VERSION ""

NS_ :

BS_:

BU_: XXX 0

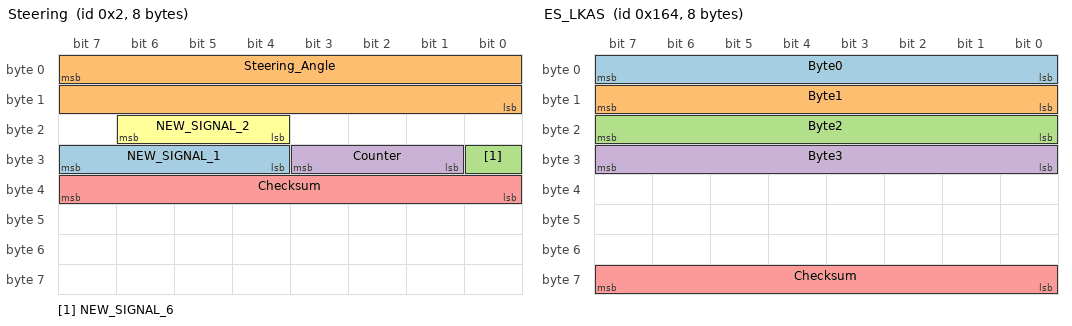
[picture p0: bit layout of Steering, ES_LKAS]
BO_ 2 Steering: 8 XXX
 SG_ NEW_SIGNAL_1 : 31|4@0- (1,0) [0|65535] "" XXX
 SG_ Steering_Angle : 7|16@0- (0.1,0) [-497|500] "degree" XXX
 SG_ NEW_SIGNAL_6 : 24|1@1+ (1,0) [0|3] "" XXX
 SG_ Counter : 25|3@1+ (1,0) [0|15] "" XXX
 SG_ Checksum : 32|8@1+ (1,0) [0|255] "" XXX
 SG_ NEW_SIGNAL_2 : 22|3@0+ (1,0) [0|7] "" XXX

BO_ 212 WHEEL_SPEEDS: 8 XXX
 SG_ FR : 16|16@1+ (0.0592,0) [0|255] "KPH" XXX
 SG_ RR : 48|16@1+ (0.0592,0) [0|127] "KPH" XXX
 SG_ RL : 32|16@1+ (0.0592,0) [0|255] "KPH" XXX
 SG_ FL : 0|16@1+ (0.0592,0) [2|255] "KPH" XXX
 SG_ Message : 7|64@0+ (1,0) [0|15] "" XXX

BO_ 352 ES_Brake: 8 XXX
 SG_ Counter : 48|3@1+ (1,0) [0|7] "" XXX
 SG_ Checksum : 56|8@1+ (1,0) [0|7] "" XXX
 SG_ Cruise_Activated : 23|1@0+ (1,0) [0|3] "" XXX
 SG_ Brake_On : 22|1@0+ (1,0) [0|3] "" XXX
 SG_ Brake_Light : 20|1@0+ (1,0) [0|2047] "" XXX
 SG_ Brake_Pressure : 0|11@1+ (1,0) [0|255] "" XXX
 SG_ Message : 7|64@0+ (1,0) [0|15] "" XXX

BO_ 353 ES_CruiseThrottle: 8 XXX
 SG_ Throttle_Cruise : 0|12@1+ (1,0) [0|255] "" XXX
 SG_ Counter_1 : 46|3@0+ (1,0) [0|15] "" XXX
 SG_ Wheel_stop : 22|1@0+ (1,0) [0|3] "" XXX
 SG_ CloseDistance : 24|8@1+ (1,0) [0|255] "" XXX
 SG_ Unknown : 18|1@1+ (1,0) [0|7] "" XXX
 SG_ Button_Speed_Down : 49|1@1+ (1,0) [0|3] "" XXX
 SG_ Button_Resume : 50|1@1+ (1,0) [0|15] "" XXX
 SG_ NEW_SIGNAL_3_Blank : 15|4@0+ (1,0) [0|15] "" XXX
 SG_ NEW_SIGNAL_2_Blank : 48|1@1+ (1,0) [0|3] "" XXX
 SG_ Checksum : 56|8@1+ (1,0) [0|15] "" XXX
 SG_ NEW_SIGNAL_9 : 17|1@1+ (1,0) [0|3] "" XXX
 SG_ Cruise_Activatedish : 16|1@1+ (1,0) [0|7] "" XXX
 SG_ NEW_SIGNAL_6_Blank : 23|1@0+ (1,0) [0|7] "" XXX
 SG_ DistanceSwap : 21|1@0+ (1,0) [0|3] "" XXX
 SG_ Brake_On : 20|1@0+ (1,0) [0|7] "" XXX
 SG_ Message : 7|64@0+ (1,0) [0|15] "" XXX

BO_ 354 ES_RPM: 8 XXX
 SG_ NEW_SIGNAL_2 : 8|1@1+ (1,0) [0|7] "" XXX
 SG_ Counter : 48|3@1+ (1,0) [0|7] "" XXX
 SG_ Cruise_Activated : 9|1@0+ (1,0) [0|3] "" XXX
 SG_ Checksum : 39|8@0+ (1,0) [0|65535] "" XXX
 SG_ RPM : 16|16@1+ (1,0) [0|255] "" XXX
 SG_ Message : 7|64@0+ (1,0) [0|15] "" XXX

BO_ 356 ES_LKAS: 8 XXX
 SG_ Byte0 : 7|8@0+ (1,0) [0|7] "" XXX
 SG_ Byte1 : 15|8@0+ (1,0) [0|7] "" XXX
 SG_ Byte2 : 23|8@0+ (1,0) [0|3] "" XXX
 SG_ Byte3 : 31|8@0+ (1,0) [0|7] "" XXX
 SG_ Checksum : 63|8@0+ (1,0) [0|15] "" XXX

BO_ 358 ES_Status: 8 XXX
 SG_ Counter : 39|3@0+ (1,0) [0|7] "" XXX
 SG_ Cruise_On : 16|1@1+ (1,0) [0|7] "" XXX
 SG_ Cruise_Activated : 17|1@1+ (1,0) [0|3] "" XXX
 SG_ Obstacle_Distance : 48|4@1+ (1,0) [0|15] "" XXX
 SG_ Cruise_Off : 22|1@0+ (1,0) [0|3] "" XXX
 SG_ Saved_Speed : 24|8@1+ (1,0) [0|255] "" XXX
 SG_ Car_Follow : 46|1@1+ (1,0) [0|255] "" XXX
 SG_ Driver_Input : 20|1@0+ (1,0) [0|15] "" XXX
 SG_ WHEELS_MOVING_2015 : 19|1@1+ (1,0) [0|3] "" XXX
 SG_ Untitled_Blank : 18|1@0+ (1,0) [0|3] "" XXX
 SG_ NEW_SIGNAL_6_Blank : 21|1@0+ (1,0) [0|3] "" XXX
 SG_ NEW_SIGNAL_5_Blank : 33|1@1+ (1,0) [0|3] "" XXX
 SG_ NEW_SIGNAL_4_Blank : 34|1@1+ (1,0) [0|7] "" XXX
 SG_ NEW_SIGNAL_1 : 35|1@0+ (1,0) [0|31] "" XXX
 SG_ Steep_Hill_Disengage : 44|1@0+ (1,0) [0|3] "" XXX
 SG_ 3SecondDisengage : 13|2@0+ (1,0) [0|3] "" XXX
 SG_ Not_Ready_Startup : 0|3@1+ (1,0) [0|7] "" XXX
 SG_ Disengage_Alert : 15|2@0+ (1,0) [0|3] "" XXX
 SG_ Message : 7|64@0+ (1,0) [0|15] "" XXX

BO_ 359 ES_LDW: 8 XXX
 SG_ 2Right_Depart : 50|1@1+ (1,0) [0|7] "" XXX
 SG_ 2All_Depart : 28|1@0+ (1,0) [0|3] "" XXX
 SG_ 3All_Depart : 52|1@0+ (1,0) [0|3] "" XXX
 SG_ Left_Depart_Front : 51|1@0+ (1,0) [0|3] "" XXX
 SG_ All_depart_2015 : 0|1@1+ (1,0) [0|255] "" XXX
 SG_ LKAS_Inactive_2017 : 36|1@1+ (1,0) [0|3] "" XXX
 SG_ LKAS_Steer_Active_2017 : 37|1@0+ (1,0) [0|3] "" XXX
 SG_ Right_Line_2017 : 24|1@1+ (1,0) [0|7] "" XXX
 SG_ Left_Line_2017 : 25|1@1+ (1,0) [0|3] "" XXX
 SG_ 1All_Depart : 31|1@0+ (1,0) [0|15] "" XXX
 SG_ 1Right_Depart_Front : 49|1@1+ (1,0) [0|3] "" XXX
 SG_ 1Right_Depart : 48|1@1+ (1,0) [0|3] "" XXX
 SG_ Message : 7|64@0+ (1,0) [0|15] "" XXX

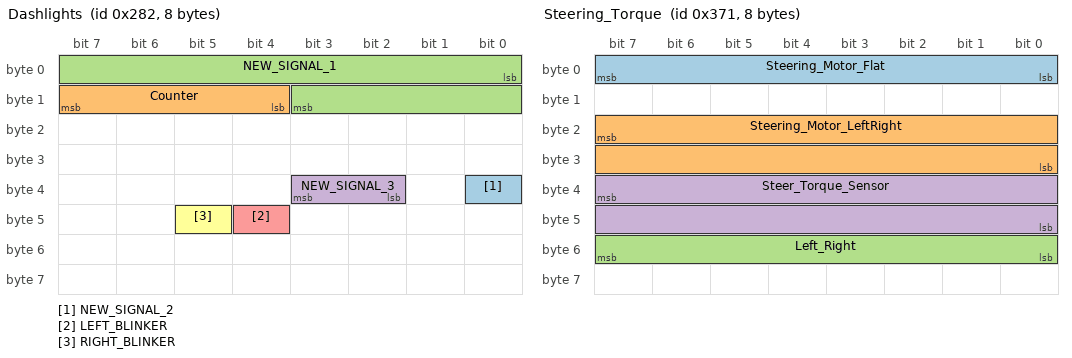
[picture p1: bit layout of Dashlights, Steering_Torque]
BO_ 642 Dashlights: 8 XXX
 SG_ NEW_SIGNAL_2 : 32|1@1+ (1,0) [0|15] "" XXX
 SG_ Counter : 15|4@0+ (1,0) [0|15] "" XXX
 SG_ NEW_SIGNAL_1 : 0|12@1+ (1,0) [0|255] "" XXX
 SG_ NEW_SIGNAL_3 : 34|2@1+ (1,0) [0|3] "" XXX
 SG_ LEFT_BLINKER : 44|1@0+ (1,0) [0|3] "" XXX
 SG_ RIGHT_BLINKER : 45|1@0+ (1,0) [0|3] "" XXX

BO_ 881 Steering_Torque: 8 XXX
 SG_ Steering_Motor_Flat : 0|8@1+ (1,0) [0|255] "" XXX
 SG_ Steering_Motor_LeftRight : 23|16@0- (1,0) [0|255] "" XXX
 SG_ Left_Right : 55|8@0- (1,0) [0|255] "" XXX
 SG_ Steer_Torque_Sensor : 39|16@0- (1,0) [0|255] "" XXX

CM_ SG_ 353 NEW_SIGNAL_3_Blank "always 2";
CM_ SG_ 353 NEW_SIGNAL_2_Blank "0";
CM_ SG_ 353 NEW_SIGNAL_9 "flipped around quick engagement";
CM_ SG_ 353 NEW_SIGNAL_6_Blank "always 1";
CM_ SG_ 353 Brake_On "long activatedish";
CM_ SG_ 354 RPM "20hz version of Transmission_Engine under Transmission";
CM_ SG_ 358 Cruise_Activated "is 1 when cruise is able to go";
CM_ SG_ 358 Car_Follow "front car detected";
CM_ SG_ 358 3SecondDisengage "seatbelt disengage";
CM_ SG_ 358 Disengage_Alert "seatbelt and steep hill disengage";
CM_ SG_ 359 2All_Depart "Left and right depart";
CM_ SG_ 359 Left_Depart_Front "warning after acceleration into car in front and left depart";
CM_ SG_ 359 All_depart_2015 "always 1 on 2017";
CM_ SG_ 359 LKAS_Inactive_2017 "1 when not steering, 0 when lkas steering";
CM_ SG_ 359 1All_Depart "Left and right depart";
CM_ SG_ 359 1Right_Depart_Front "object in front, right depart, hill steep and seatbelt disengage alert ";
CM_ SG_ 359 1Right_Depart "right depart, hill steep and seatbelt disengage";
CM_ SG_ 642 Counter "Affected by signals";
CM_ SG_ 642 RIGHT_BLINKER "0 off, 2 right, 1 left";
CM_ SG_ 880 Steering_Voltage_Flat "receives later than 371";
CM_ SG_ 880 NEW_SIGNAL_1 "0 in 2017";
CM_ SG_ 880 NEW_SIGNAL_4_2017 "1 in 2017";
CM_ SG_ 880 NEW_SIGNAL_5_2017 "1 in 2017";
CM_ SG_ 881 Steering_Motor_Flat "Possibly motor voltage";
CM_ SG_ 881 Left_Right "Missing extra larger bits";

CM_ "CHFFR_METRIC 2 STEER_ANGLE STEER_ANGLE 0.36 180";
